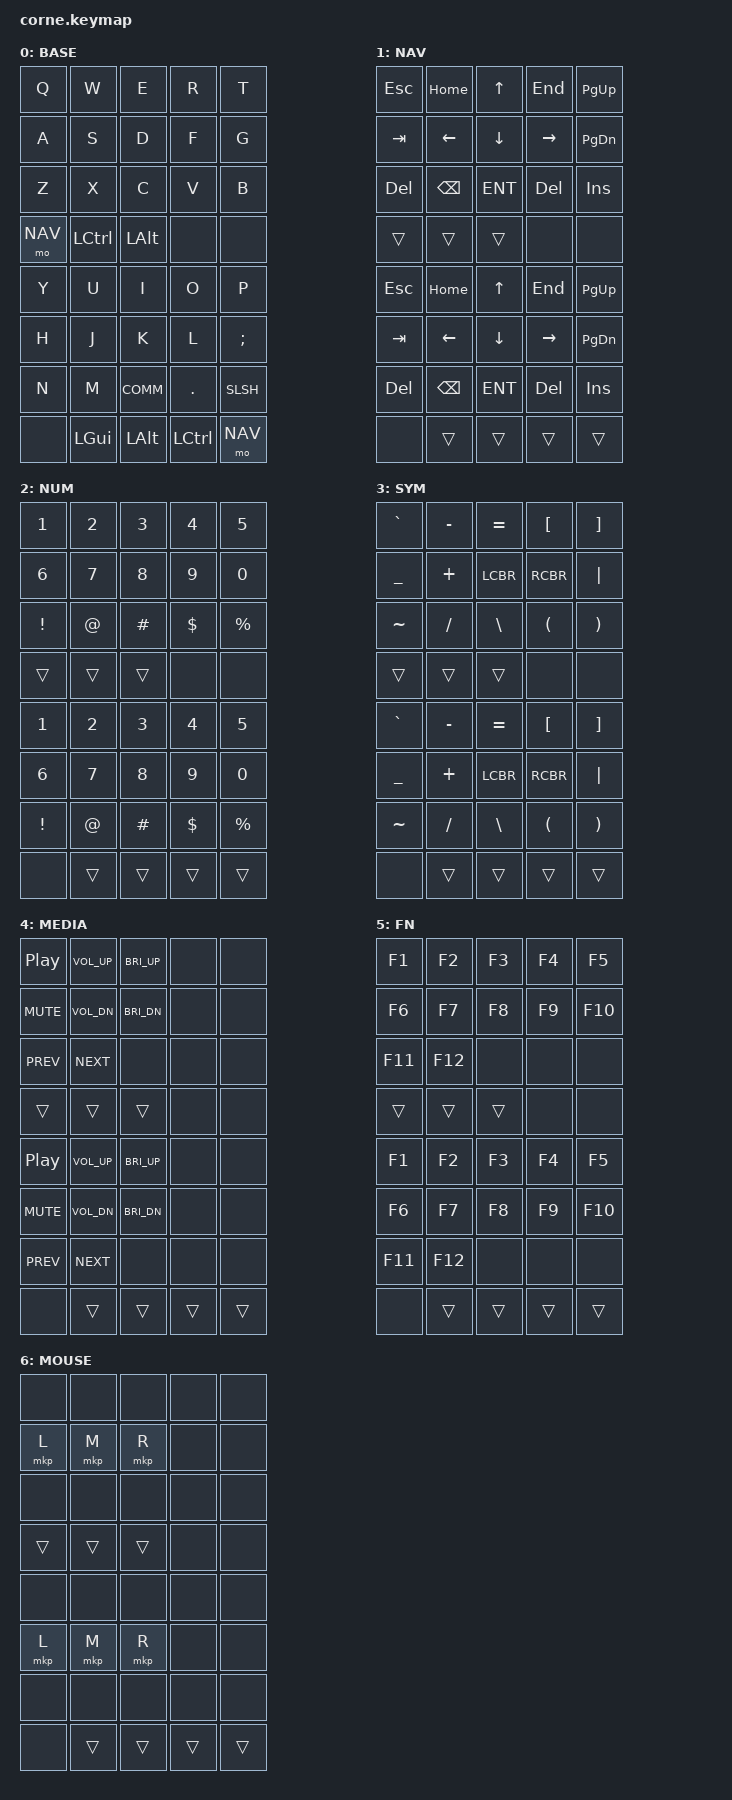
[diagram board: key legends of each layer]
#include <behaviors.dtsi>
#include <dt-bindings/zmk/matrix_transform.h>

/ {
    keymap {
        compatible = "zmk,keymap";

        default_layer {
            label = "BASE";
            bindings = <
                // Left Hand (5x3 + 3 thumb keys)
                &kp Q    &kp W    &kp E    &kp R    &kp T
                &kp A    &kp S    &kp D    &kp F    &kp G
                &kp Z    &kp X    &kp C    &kp V    &kp B
                &mo NAV  &kp LCTL &kp LALT &none    &none

                // Right Hand (5x3 + 3 thumb keys)
                &kp Y    &kp U    &kp I    &kp O    &kp P
                &kp H    &kp J    &kp K    &kp L    &kp SCLN
                &kp N    &kp M    &kp COMM &kp DOT  &kp SLSH
                &none    &kp LGUI &kp LALT &kp LCTL &mo NAV
            >;
        };

        nav_layer {
            label = "NAV";
            bindings = <
                // Left Hand
                &kp ESC  &kp HOME &kp UP   &kp END  &kp PG_UP
                &kp TAB  &kp LEFT &kp DOWN &kp RIGHT &kp PG_DN
                &kp DEL  &kp BSPC &kp ENT  &kp DEL  &kp INS
                &trans   &trans   &trans   &none    &none

                // Right Hand
                &kp ESC  &kp HOME &kp UP   &kp END  &kp PG_UP
                &kp TAB  &kp LEFT &kp DOWN &kp RIGHT &kp PG_DN
                &kp DEL  &kp BSPC &kp ENT  &kp DEL  &kp INS
                &none    &trans   &trans   &trans   &trans
            >;
        };

        num_layer {
            label = "NUM";
            bindings = <
                // Left Hand
                &kp N1   &kp N2   &kp N3   &kp N4   &kp N5
                &kp N6   &kp N7   &kp N8   &kp N9   &kp N0
                &kp EXCL &kp AT   &kp HASH &kp DLLR &kp PRCNT
                &trans   &trans   &trans   &none    &none

                // Right Hand
                &kp N1   &kp N2   &kp N3   &kp N4   &kp N5
                &kp N6   &kp N7   &kp N8   &kp N9   &kp N0
                &kp EXCL &kp AT   &kp HASH &kp DLLR &kp PRCNT
                &none    &trans   &trans   &trans   &trans
            >;
        };

        sym_layer {
            label = "SYM";
            bindings = <
                // Left Hand
                &kp GRAVE &kp MINUS &kp EQUAL &kp LBKT &kp RBKT
                &kp UNDER &kp PLUS  &kp LCBR  &kp RCBR &kp PIPE
                &kp TILDE &kp SLASH &kp BSLH  &kp LPAR &kp RPAR
                &trans    &trans    &trans    &none    &none

                // Right Hand
                &kp GRAVE &kp MINUS &kp EQUAL &kp LBKT &kp RBKT
                &kp UNDER &kp PLUS  &kp LCBR  &kp RCBR &kp PIPE
                &kp TILDE &kp SLASH &kp BSLH  &kp LPAR &kp RPAR
                &none     &trans    &trans    &trans   &trans
            >;
        };

        media_layer {
            label = "MEDIA";
            bindings = <
                // Left Hand
                &kp C_PP  &kp C_VOL_UP &kp C_BRI_UP &none     &none
                &kp C_MUTE&kp C_VOL_DN &kp C_BRI_DN &none     &none
                &kp C_PREV&kp C_NEXT   &none        &none     &none
                &trans    &trans       &trans       &none     &none

                // Right Hand
                &kp C_PP  &kp C_VOL_UP &kp C_BRI_UP &none     &none
                &kp C_MUTE&kp C_VOL_DN &kp C_BRI_DN &none     &none
                &kp C_PREV&kp C_NEXT   &none        &none     &none
                &none     &trans       &trans       &trans    &trans
            >;
        };

        fn_layer {
            label = "FN";
            bindings = <
                // Left Hand
                &kp F1    &kp F2    &kp F3    &kp F4    &kp F5
                &kp F6    &kp F7    &kp F8    &kp F9    &kp F10
                &kp F11   &kp F12   &none     &none     &none
                &trans    &trans    &trans    &none     &none

                // Right Hand
                &kp F1    &kp F2    &kp F3    &kp F4    &kp F5
                &kp F6    &kp F7    &kp F8    &kp F9    &kp F10
                &kp F11   &kp F12   &none     &none     &none
                &none     &trans    &trans    &trans    &trans
            >;
        };

        mouse_layer {
            label = "MOUSE";
            bindings = <
                // Left Hand
                &none     &none     &none     &none     &none
                &mkp L    &mkp M    &mkp R    &none     &none
                &none     &none     &none     &none     &none
                &trans    &trans    &trans    &none     &none

                // Right Hand
                &none     &none     &none     &none     &none
                &mkp L    &mkp M    &mkp R    &none     &none
                &none     &none     &none     &none     &none
                &none     &trans    &trans    &trans    &trans
            >;
        };
    };

    
 {
    matrix_transform_left: matrix_transform {
        compatible = "zmk,matrix-transform";
        label = "Matrix Transform";
        rows = <4>; // 3 main rows + 1 thumb row
        columns = <5>; // 5 columns

       map = <
RC(0,0) RC(0,1) RC(0,2) RC(0,3) RC(0,4) RC(0,5)  RC(0,6) RC(0,7) RC(0,8) RC(0,9) RC(0,10) RC(0,11)
RC(1,0) RC(1,1) RC(1,2) RC(1,3) RC(1,4) RC(1,5)  RC(1,6) RC(1,7) RC(1,8) RC(1,9) RC(1,10) RC(1,11)
RC(2,0) RC(2,1) RC(2,2) RC(2,3) RC(2,4) RC(2,5)  RC(2,6) RC(2,7) RC(2,8) RC(2,9) RC(2,10) RC(2,11)
                        RC(3,3) RC(3,4) RC(3,5)  RC(3,6) RC(3,7) RC(3,8)
		>;
    };
};


    rgb_underglow: rgb_underglow {
        compatible = "zmk,rgb-underglow";
        chain-length = <12>; // Adjust based on your RGB LED count
        color-map = /bits/ 8 <0xFF 0x00 0x00 0x00 0xFF 0x00 0x00 0x00 0xFF>; // RGB color map
        animation-speed = <100>; // Adjust animation speed
    };

    mouse_keys {
        compatible = "zmk,mouse-keys";
        delay-ms = <200>; // Delay before mouse keys activate
        time-to-max-speed-ms = <300>; // Time to reach max speed
        acceleration-exponent = <1>; // Acceleration curve
    };
};
